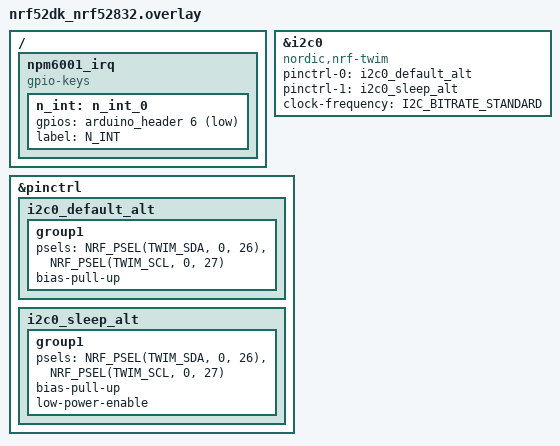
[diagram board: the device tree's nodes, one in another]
&i2c0 {
	compatible = "nordic,nrf-twim";
	status = "okay";

	pinctrl-0 = <&i2c0_default_alt>;
	pinctrl-1 = <&i2c0_sleep_alt>;
	pinctrl-names = "default", "sleep";
	clock-frequency = <I2C_BITRATE_STANDARD>;
};

&pinctrl {
	i2c0_default_alt: i2c0_default_alt {
		group1 {
			psels = <NRF_PSEL(TWIM_SDA, 0, 26)>,
				<NRF_PSEL(TWIM_SCL, 0, 27)>;
			bias-pull-up;
		};
	};

	i2c0_sleep_alt: i2c0_sleep_alt {
		group1 {
			psels = <NRF_PSEL(TWIM_SDA, 0, 26)>,
				<NRF_PSEL(TWIM_SCL, 0, 27)>;
			bias-pull-up;
			low-power-enable;
		};
	};
};

/ {
	npm6001_irq {
		compatible = "gpio-keys";
		n_int: n_int_0 {
			gpios = <&arduino_header 6 (GPIO_PULL_UP | GPIO_ACTIVE_LOW)>;	/* D0 */
			label = "N_INT";
		};
	};
};
